# GD32E50x_CL register map
File version: 1.0
CPU: CM33 r0p4, little endian, MPU, FPU, 4 interrupt priority bits
Registers are 32-bit, read-write, reset 0x0 unless marked. A register's access mark holds for its fields unless they carry their own. Offsets are from the block's base; [hi:lo] are bit positions; {n}, {i} and the like mark numbered series.

## DMA0 — DMA controller
Base 0x40020000
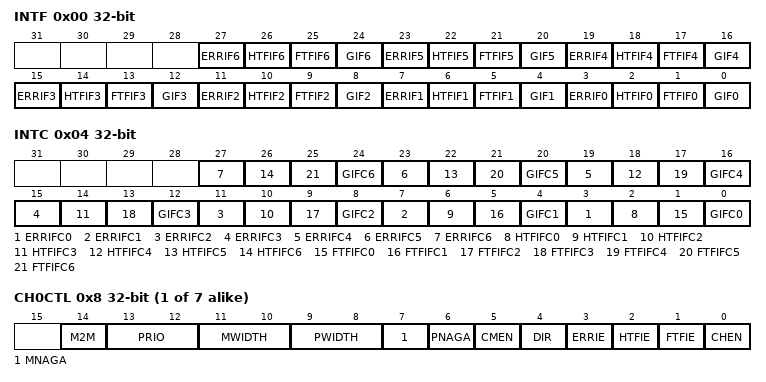
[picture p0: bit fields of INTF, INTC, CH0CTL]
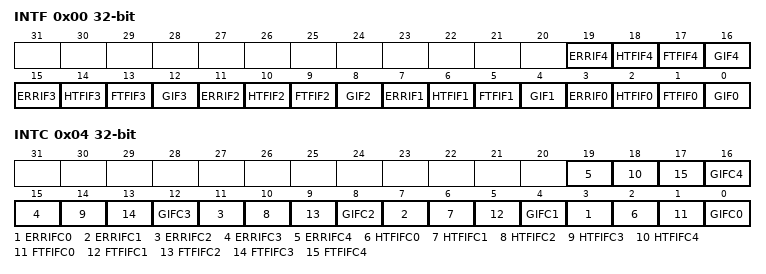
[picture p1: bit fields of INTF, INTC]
0x00 INTF ro — Interrupt flag register
  [4n+3] ERRIF{n} (n=0..6) — Error flag of channel {n}
  [4n+2] HTFIF{n} (n=0..6) — Half transfer finish flag of channel {n}
  [4n+1] FTFIF{n} (n=0..6) — Full Transfer finish flag of channe {n}
  [4n] GIF{n} (n=0..6) — Global interrupt flag of channel {n}
0x04 INTC wo — Interrupt flag clear register
  [4n+3] ERRIFC{n} (n=0..6) — Clear bit for error flag of channel {n}
  [4n+2] HTFIFC{n} (n=0..6) — Clear bit for half transfer finish flag of channel {n}
  [4n+1] FTFIFC{n} (n=0..6) — Clear bit for full transfer finish flag of channel {n}
  [4n] GIFC{n} (n=0..6) — Clear global interrupt flag of channel {n}
{0x8+0x14*i} CH{i}CTL (i=0..6) — Channel {i} control register
  [14] M2M — Memory to Memory Mode
  [13:12] PRIO — Priority level
  [11:10] MWIDTH — Transfer data size of memory
  [9:8] PWIDTH — Transfer data size of peripheral
  [7] MNAGA — Next address generation algorithm of memory
  [6] PNAGA — Next address generation algorithm of peripheral
  [5] CMEN — Circular mode enable
  [4] DIR — Transfer direction
  [3] ERRIE — Enable bit for channel error interrupt
  [2] HTFIE — Enable bit for channel half transfer finish interrupt
  [1] FTFIE — Enable bit for channel full transfer finish interrupt
  [0] CHEN — Channel enable
{0xC+0x14*i} CH{i}CNT (i=0..6) — Channel {i} counter register
  [15:0] CNT — Transfer counter
{0x10+0x14*i} CH{i}PADDR (i=0..6) — Channel {i} peripheral base address register
  [31:0] PADDR — Peripheral base address
{0x14+0x14*i} CH{i}MADDR (i=0..6) — Channel {i} memory base address register
  [31:0] MADDR — Memory base address

## DMA1 — DMA controller
Base 0x40020400
Registers as DMA0, without CH5CTL, CH5CNT, CH5PADDR, CH5MADDR, CH6CTL, CH6CNT, CH6PADDR, CH6MADDR; these are added or differ:
0x00 INTF ro — Interrupt flag register
  [4n+3] ERRIF{n} (n=0..4) — Error flag of channel {n}
  [4n+2] HTFIF{n} (n=0..4) — Half transfer finish flag of channel {n}
  [4n+1] FTFIF{n} (n=0..4) — Full Transfer finish flag of channe {n}
  [4n] GIF{n} (n=0..4) — Global interrupt flag of channel {n}
0x04 INTC wo — Interrupt flag clear register
  [4n+3] ERRIFC{n} (n=0..4) — Clear bit for error flag of channel {n}
  [4n+2] HTFIFC{n} (n=0..4) — Clear bit for half transfer finish flag of channel {n}
  [4n+1] FTFIFC{n} (n=0..4) — Clear bit for full transfer finish flag of channel {n}
  [4n] GIFC{n} (n=0..4) — Clear global interrupt flag of channel {n}

## ENET_MAC_FCTH — MAC flow control threshold register
Base 0x40029080
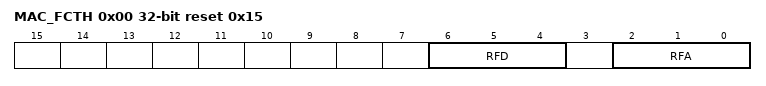
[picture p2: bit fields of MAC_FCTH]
0x00 MAC_FCTH reset 0x15 — Ethernet MAC flow control threshold register
  [6:4] RFD — Threshold of deactive flow control
  [2:0] RFA — Threshold of active flow control

## ENET_MSC — Ethernet: MAC statistics counters
Base 0x40028100
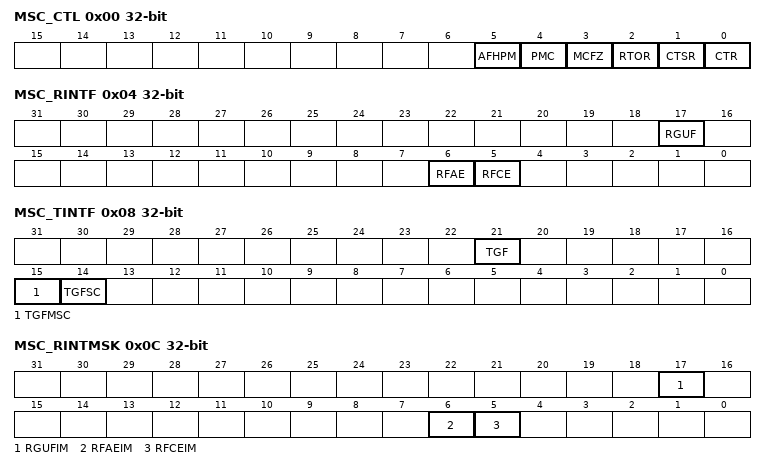
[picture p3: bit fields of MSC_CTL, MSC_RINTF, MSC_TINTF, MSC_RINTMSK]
0x00 MSC_CTL — Ethernet MSC control register (MSC_CTL)
  [5] AFHPM — Almost full or half preset mode
  [4] PMC wo — Preset MSC counter
  [3] MCFZ — MSC counter freeze
  [2] RTOR — Reset on read
  [1] CTSR — Counter stop rollover
  [0] CTR — Counter reset
0x04 MSC_RINTF ro — Ethernet MSC receive interrupt flag register (MSC_RINTF)
  [17] RGUF — Received Good Unicast Frames
  [6] RFAE — Received frames alignment error
  [5] RFCE — Received frames CRC error
0x08 MSC_TINTF ro — Ethernet MSC transmit interrupt flag register (MSC_TINTF)
  [21] TGF — Transmitted good frames
  [15] TGFMSC — Transmitted good frames more single collision
  [14] TGFSC — Transmitted good frames single collision
0x0C MSC_RINTMSK — Ethernet MSC receive interrupt mask register (MSC_RINTMSK)
  [17] RGUFIM — Received good unicast frames interrupt mask
  [6] RFAEIM — Received frames alignment error interrupt mask
  [5] RFCEIM — Received frame CRC error interrupt mask
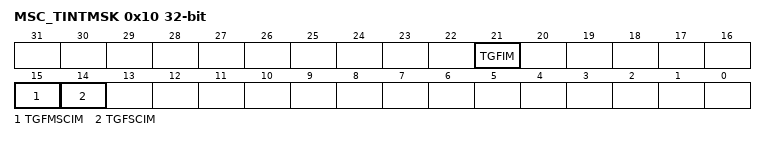
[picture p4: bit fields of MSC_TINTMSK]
0x10 MSC_TINTMSK — Ethernet MSC transmit interrupt mask register (MSC_TINTMSK)
  [21] TGFIM — Transmitted good frames interrupt mask
  [15] TGFMSCIM — Transmitted good frames more single interrupt collision mask
  [14] TGFSCIM — Transmitted good frames single collision interrupt mask
0x4C MSC_SCCNT ro — Ethernet MSC transmitted good frames after a single collision counter
  [31:0] SCC — Transmitted good frames after a single collision counter
0x50 MSC_MSCCNT ro — Ethernet MSC transmitted good frames after more than a single collision
  [31:0] MSCC — Transmitted good frames after more than a single collision counter
0x68 MSC_TGFCNT ro — Ethernet MSC transmitted good frames counter register
  [31:0] TGF — Transmitted good frames counter
0x94 MSC_RFCECNT ro — Ethernet MSC received frames with CRC error counter register
  [31:0] RFCER — Received frames with CRC error counter
0x98 MSC_RFAECNT ro — Ethernet MSC received frames with alignment error counter register
  [31:0] RFAER — Received frames with alignment error counter
0xC4 MSC_RGUFCNT ro — MSC received good unicast frames counter register
  [31:0] RGUF — Received good unicast frames counter
